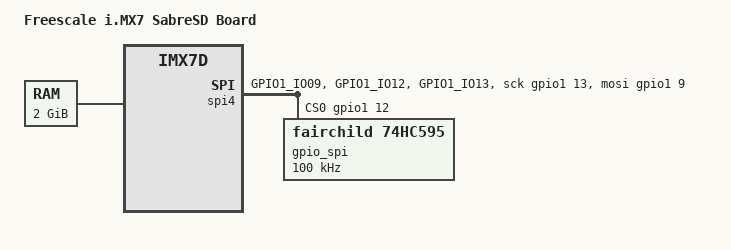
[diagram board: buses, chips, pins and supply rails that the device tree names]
/*
 * Copyright 2017 NXP
 *
 * SPDX-License-Identifier:	GPL-2.0+
 */

/dts-v1/;

#include "imx7d.dtsi"

/ {
	model = "Freescale i.MX7 SabreSD Board";
	compatible = "fsl,imx7d-sdb", "fsl,imx7d";

	memory {
		reg = <0x80000000 0x80000000>;
	};

	spi4 {
		compatible = "spi-gpio";
		pinctrl-names = "default";
		pinctrl-0 = <&pinctrl_spi1>;
		status = "okay";
		gpio-sck = <&gpio1 13 0>;
		gpio-mosi = <&gpio1 9 0>;
		cs-gpios = <&gpio1 12 0>;
		num-chipselects = <1>;
		#address-cells = <1>;
		#size-cells = <0>;

		gpio_spi: gpio_spi@0 {
			compatible = "fairchild,74hc595";
			gpio-controller;
			#gpio-cells = <2>;
			reg = <0>;
			registers-number = <1>;
			registers-default = /bits/ 8 <0x74>; /* Enable PERI_3V3, SENSOR_RST_B and HDMI_RST*/
			spi-max-frequency = <100000>;
		};
	};
};

&iomuxc {
	imx7d-sdb {
		pinctrl_spi1: spi1grp {
			fsl,pins = <
				MX7D_PAD_GPIO1_IO09__GPIO1_IO9	0x59
				MX7D_PAD_GPIO1_IO12__GPIO1_IO12	0x59
				MX7D_PAD_GPIO1_IO13__GPIO1_IO13	0x59
			>;
		};
	};

};
